# apollo1 register map
Vendor: Ambiq Micro; Series: Apollo; File version: 1.0
CPU: CM4 r1p0, little endian, MPU, FPU, 3 interrupt priority bits
Registers are 32-bit, read-write, reset 0x0 unless marked. A register's access mark holds for its fields unless they carry their own. Offsets are from the block's base; [hi:lo] are bit positions; {n}, {i} and the like mark numbered series; 'fields as' and 'values as' point back to an identical list.

## CTIMER — Counter/Timer
Base 0x40008000
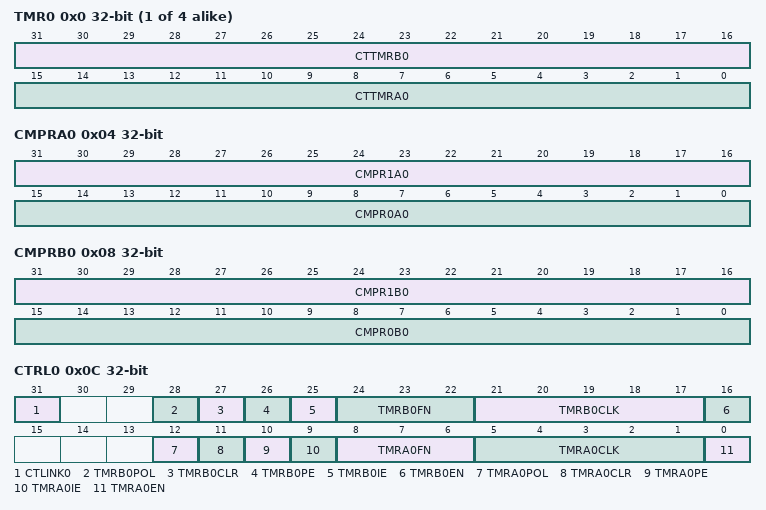
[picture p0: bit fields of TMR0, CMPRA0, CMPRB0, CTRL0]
{0x0+0x10*i} TMR{i} (i=0..3) — Counter/Timer Register
  [31:16] CTTMRB{i} — Counter/Timer B{i}.
  [15:0] CTTMRA{i} — Counter/Timer A{i}.
0x04 CMPRA0 — Counter/Timer A0 Compare Registers
  [31:16] CMPR1A0 — Counter/Timer A0 Compare Register 1. Holds the upper limit for timer half A.
  [15:0] CMPR0A0 — Counter/Timer A0 Compare Register 0. Holds the lower limit for timer half A.
0x08 CMPRB0 — Counter/Timer B0 Compare Registers
  [31:16] CMPR1B0 — Counter/Timer B0 Compare Register 1. Holds the upper limit for timer half B.
  [15:0] CMPR0B0 — Counter/Timer B0 Compare Register 0. Holds the lower limit for timer half B.
0x0C CTRL0 — Counter/Timer Control
  [31] CTLINK0 — Counter/Timer A0/B0 Link bit.
    0=TWO_16BIT_TIMERS (Use A0/B0 timers as two independent 16-bit timers (default). value.); 1=32BIT_TIMER (Link A0/B0 timers into a single 32-bit timer. value.)
  [28] TMRB0POL — Counter/Timer B0 output polarity.
    0=NORMAL (The polarity of the TMRPINB0 pin is the same as the timer output. value.); 1=INVERTED (The polarity of the TMRPINB0 pin is the inverse of the timer output. value.)
  [27] TMRB0CLR — Counter/Timer B0 Clear bit.
    0=RUN (Allow counter/timer B0 to run value.); 1=CLEAR (Holds counter/timer B0 at 0x0000. value.)
  [26] TMRB0PE — Counter/Timer B0 Output Enable bit.
    0=DIS (Counter/Timer B holds the TMRPINB signal at the value TMRB0POL. value.); 1=EN (Enable counter/timer B0 to generate a signal on TMRPINB. value.)
  [25] TMRB0IE — Counter/Timer B0 Interrupt Enable bit.
    0=DIS (Disable counter/timer B0 from generating an interrupt. value.); 1=EN (Enable counter/timer B0 to generate an interrupt. value.)
  [24:22] TMRB0FN — Counter/Timer B0 Function Select.
    0=SINGLECOUNT (Single count (output toggles and sticks). Count to CMPR0B0, stop. value.); 1=REPEATEDCOUNT (Repeated count (periodic 1-clock-cycle-wide pulses). Count to CMPR0B0, restart. value.); 2=PULSE_ONCE (Pulse once (aka one-shot). Count to CMPR0B0, assert, count to CMPR1B, deassert, stop. value.); 3=PULSE_CONT (Pulse continously. Count to CMPR0B0, assert, count to CMPR1B0, deassert, restart. value.); 4=CONTINUOUS (Continuous run (aka Free Run). Count continuously. value.)
  [21:17] TMRB0CLK — Counter/Timer B0 Clock Select.
    0=TMRPIN (Clock source is TMRPINB. value.); 1=HFRC (Clock source is the HFRC value.); 2=HFRC_DIV8 (Clock source is HFRC / 8 value.); 3=HFRC_DIV128 (Clock source is HFRC / 128 value.); 4=HFRC_DIV512 (Clock source is HFRC / 512 value.); 5=HFRC_DIV2K (Clock source is HFRC / 2048 value.); 6=XT (Clock source is the XT (uncalibrated). value.); 7=XT_DIV2 (Clock source is XT / 2 value.); 8=XT_DIV16 (Clock source is XT / 16 value.); 9=XT_DIV256 (Clock source is XT / 256 value.); 10=LFRC_DIV2 (Clock source is LFRC / 2 value.); 11=LFRC_DIV32 (Clock source is LFRC / 32 value.); 12=LFRC_DIV1K (Clock source is LFRC / 1024 value.); 13=LFRC (Clock source is LFRC / 16K value.); 14=RTC_100HZ (Clock source is 100 Hz from the current RTC oscillator. value.); 15=HCLK (Clock source is HCLK. value.); 16=BUCKB (Clock source is buck converter stream B. value.)
  [16] TMRB0EN — Counter/Timer B0 Enable bit.
    0=DIS (Counter/Timer B0 Disable. value.); 1=EN (Counter/Timer B0 Enable. value.)
  [12] TMRA0POL — Counter/Timer A0 output polarity.
    0=NORMAL (The polarity of the TMRPINA0 pin is the same as the timer output. value.); 1=INVERTED (The polarity of the TMRPINA0 pin is the inverse of the timer output. value.)
  [11] TMRA0CLR — Counter/Timer A0 Clear bit.
    0=RUN (Allow counter/timer A0 to run value.); 1=CLEAR (Holds counter/timer A0 at 0x0000. value.)
  [10] TMRA0PE — Counter/Timer A0 Output Enable bit.
    0=DIS (Counter/Timer A holds the TMRPINA signal at the value TMRA0POL. value.); 1=EN (Enable counter/timer B0 to generate a signal on TMRPINB. value.)
  [9] TMRA0IE — Counter/Timer A0 Interrupt Enable bit.
    0=DIS (Disable counter/timer A0 from generating an interrupt. value.); 1=EN (Enable counter/timer A0 to generate an interrupt. value.)
  [8:6] TMRA0FN — Counter/Timer A0 Function Select.
    0=SINGLECOUNT (Single count (output toggles and sticks). Count to CMPR0A0, stop. value.); 1=REPEATEDCOUNT (Repeated count (periodic 1-clock-cycle-wide pulses). Count to CMPR0A0, restart. value.); 2=PULSE_ONCE (Pulse once (aka one-shot). Count to CMPR0A0, assert, count to CMPR1B, deassert, stop. value.); 3=PULSE_CONT (Pulse continously. Count to CMPR0A0, assert, count to CMPR1A0, deassert, restart. value.); 4=CONTINUOUS (Continuous run (aka Free Run). Count continuously. value.)
  [5:1] TMRA0CLK — Counter/Timer A0 Clock Select.
    0=TMRPIN (Clock source is TMRPINA. value.); 1=HFRC (Clock source is the HFRC value.); 2=HFRC_DIV8 (Clock source is HFRC / 8 value.); 3=HFRC_DIV128 (Clock source is HFRC / 128 value.); 4=HFRC_DIV512 (Clock source is HFRC / 512 value.); 5=HFRC_DIV2K (Clock source is HFRC / 2048 value.); 6=XT (Clock source is the XT (uncalibrated). value.); 7=XT_DIV2 (Clock source is XT / 2 value.); 8=XT_DIV16 (Clock source is XT / 16 value.); 9=XT_DIV256 (Clock source is XT / 256 value.); 10=LFRC_DIV2 (Clock source is LFRC / 2 value.); 11=LFRC_DIV32 (Clock source is LFRC / 32 value.); 12=LFRC_DIV1K (Clock source is LFRC / 1024 value.); 13=LFRC (Clock source is LFRC / 16K value.); 14=RTC_100HZ (Clock source is 100 Hz from the current RTC oscillator. value.); 15=HCLK (Clock source is HCLK. value.); 16=BUCKA (Clock source is buck converter stream A. value.)
  [0] TMRA0EN — Counter/Timer A0 Enable bit.
    0=DIS (Counter/Timer A0 Disable. value.); 1=EN (Counter/Timer A0 Enable. value.)
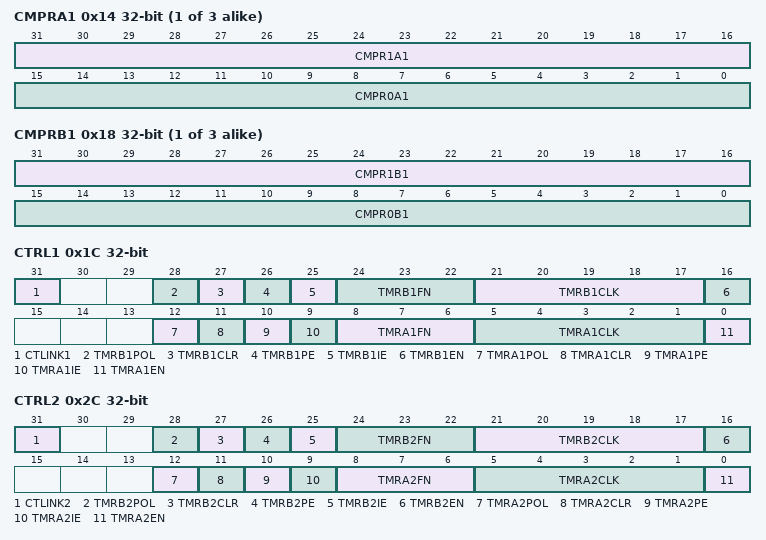
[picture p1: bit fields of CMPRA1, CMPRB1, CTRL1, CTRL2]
{0x4+0x10*i} CMPRA{i} (i=1..3) — Counter/Timer A{i} Compare Registers
  [31:16] CMPR1A{i} — Counter/Timer A{i} Compare Register 1.
  [15:0] CMPR0A{i} — Counter/Timer A{i} Compare Register 0.
{0x8+0x10*i} CMPRB{i} (i=1..3) — Counter/Timer B{i} Compare Registers
  [31:16] CMPR1B{i} — Counter/Timer B{i} Compare Register 1.
  [15:0] CMPR0B{i} — Counter/Timer B{i} Compare Register 0.
0x1C CTRL1 — Counter/Timer Control
  [31] CTLINK1 — Counter/Timer A1/B1 Link bit.
    0=TWO_16BIT_TIMERS (Use A0/B0 timers as two independent 16-bit timers (default). value.); 1=32BIT_TIMER (Link A1/B1 timers into a single 32-bit timer. value.)
  [28] TMRB1POL — Counter/Timer B1 output polarity.
    0=NORMAL (The polarity of the TMRPINB1 pin is the same as the timer output. value.); 1=INVERTED (The polarity of the TMRPINB1 pin is the inverse of the timer output. value.)
  [27] TMRB1CLR — Counter/Timer B1 Clear bit.
    0=RUN (Allow counter/timer B1 to run value.); 1=CLEAR (Holds counter/timer B1 at 0x0000. value.)
  [26] TMRB1PE — Counter/Timer B1 Output Enable bit.
    0=DIS (Counter/Timer B holds the TMRPINB signal at the value TMRB1POL. value.); 1=EN (Enable counter/timer B1 to generate a signal on TMRPINB. value.)
  [25] TMRB1IE — Counter/Timer B1 Interrupt Enable bit.
    0=DIS (Disable counter/timer B1 from generating an interrupt. value.); 1=EN (Enable counter/timer B1 to generate an interrupt. value.)
  [24:22] TMRB1FN — Counter/Timer B1 Function Select.
    0=SINGLECOUNT (Single count (output toggles and sticks). Count to CMPR0B1, stop. value.); 1=REPEATEDCOUNT (Repeated count (periodic 1-clock-cycle-wide pulses). Count to CMPR0B1, restart. value.); 2=PULSE_ONCE (Pulse once (aka one-shot). Count to CMPR0B1, assert, count to CMPR1B, deassert, stop. value.); 3=PULSE_CONT (Pulse continously. Count to CMPR0B1, assert, count to CMPR1B1, deassert, restart. value.); 4=CONTINUOUS (Continuous run (aka Free Run). Count continuously. value.)
  [21:17] TMRB1CLK — Counter/Timer B1 Clock Select.
    values as CTRL0.TMRB0CLK
  [16] TMRB1EN — Counter/Timer B1 Enable bit.
    0=DIS (Counter/Timer B1 Disable. value.); 1=EN (Counter/Timer B1 Enable. value.)
  [12] TMRA1POL — Counter/Timer A1 output polarity.
    0=NORMAL (The polarity of the TMRPINA1 pin is the same as the timer output. value.); 1=INVERTED (The polarity of the TMRPINA1 pin is the inverse of the timer output. value.)
  [11] TMRA1CLR — Counter/Timer A1 Clear bit.
    0=RUN (Allow counter/timer A1 to run value.); 1=CLEAR (Holds counter/timer A1 at 0x0000. value.)
  [10] TMRA1PE — Counter/Timer A1 Output Enable bit.
    0=DIS (Counter/Timer A holds the TMRPINA signal at the value TMRA1POL. value.); 1=EN (Enable counter/timer A1 to generate a signal on TMRPINA. value.)
  [9] TMRA1IE — Counter/Timer A1 Interrupt Enable bit.
    0=DIS (Disable counter/timer A1 from generating an interrupt. value.); 1=EN (Enable counter/timer A1 to generate an interrupt. value.)
  [8:6] TMRA1FN — Counter/Timer A1 Function Select.
    0=SINGLECOUNT (Single count (output toggles and sticks). Count to CMPR0A1, stop. value.); 1=REPEATEDCOUNT (Repeated count (periodic 1-clock-cycle-wide pulses). Count to CMPR0A1, restart. value.); 2=PULSE_ONCE (Pulse once (aka one-shot). Count to CMPR0A1, assert, count to CMPR1B, deassert, stop. value.); 3=PULSE_CONT (Pulse continously. Count to CMPR0A1, assert, count to CMPR1A1, deassert, restart. value.); 4=CONTINUOUS (Continuous run (aka Free Run). Count continuously. value.)
  [5:1] TMRA1CLK — Counter/Timer A1 Clock Select.
    0=TMRPIN (Clock source is TMRPINA. value.); 1=HFRC (Clock source is the HFRC value.); 2=HFRC_DIV8 (Clock source is the HFRC / 8 value.); 3=HFRC_DIV128 (Clock source is HFRC / 128 value.); 4=HFRC_DIV512 (Clock source is HFRC / 512 value.); 5=HFRC_DIV2K (Clock source is HFRC / 2048 value.); 6=XT (Clock source is the XT (uncalibrated). value.); 7=XT_DIV2 (Clock source is XT / 2 value.); 8=XT_DIV16 (Clock source is XT / 16 value.); 9=XT_DIV256 (Clock source is XT / 256 value.); 10=LFRC_DIV2 (Clock source is LFRC / 2 value.); 11=LFRC_DIV32 (Clock source is LFRC / 32 value.); 12=LFRC_DIV1K (Clock source is LFRC / 1024 value.); 13=LFRC (Clock source is LFRC / 16K value.); 14=RTC_100HZ (Clock source is 100 Hz from the current RTC oscillator. value.); 15=HCLK (Clock source is HCLK. value.); 16=BUCKA (Clock source is buck converter stream A. value.)
  [0] TMRA1EN — Counter/Timer A1 Enable bit.
    0=DIS (Counter/Timer A1 Disable. value.); 1=EN (Counter/Timer A1 Enable. value.)
0x2C CTRL2 — Counter/Timer Control
  [31] CTLINK2 — Counter/Timer A2/B2 Link bit.
    0=TWO_16BIT_TIMERS (Use A0/B0 timers as two independent 16-bit timers (default). value.); 1=32BIT_TIMER (Link A2/B2 timers into a single 32-bit timer. value.)
  [28] TMRB2POL — Counter/Timer B2 output polarity.
    0=NORMAL (The polarity of the TMRPINB2 pin is the same as the timer output. value.); 1=INVERTED (The polarity of the TMRPINB2 pin is the inverse of the timer output. value.)
  [27] TMRB2CLR — Counter/Timer B2 Clear bit.
    0=RUN (Allow counter/timer B2 to run value.); 1=CLEAR (Holds counter/timer B2 at 0x0000. value.)
  [26] TMRB2PE — Counter/Timer B2 Output Enable bit.
    0=DIS (Counter/Timer B holds the TMRPINB signal at the value TMRB2POL. value.); 1=EN (Enable counter/timer B2 to generate a signal on TMRPINB. value.)
  [25] TMRB2IE — Counter/Timer B2 Interrupt Enable bit.
    0=DIS (Disable counter/timer B2 from generating an interrupt. value.); 1=EN (Enable counter/timer B2 to generate an interrupt. value.)
  [24:22] TMRB2FN — Counter/Timer B2 Function Select.
    0=SINGLECOUNT (Single count (output toggles and sticks). Count to CMPR0B2, stop. value.); 1=REPEATEDCOUNT (Repeated count (periodic 1-clock-cycle-wide pulses). Count to CMPR0B2, restart. value.); 2=PULSE_ONCE (Pulse once (aka one-shot). Count to CMPR0B2, assert, count to CMPR1B, deassert, stop. value.); 3=PULSE_CONT (Pulse continously. Count to CMPR0B2, assert, count to CMPR1B2, deassert, restart. value.); 4=CONTINUOUS (Continuous run (aka Free Run). Count continuously. value.)
  [21:17] TMRB2CLK — Counter/Timer B2 Clock Select.
    0=TMRPIN (Clock source is TMRPINB. value.); 1=HFRC (Clock source is the HFRC value.); 2=HFRC_DIV8 (Clock source is HFRC / 8 value.); 3=HFRC_DIV128 (Clock source is HFRC / 128 value.); 4=HFRC_DIV512 (Clock source is HFRC / 512 value.); 5=HFRC_DIV2K (Clock source is HFRC / 2048 value.); 6=XT (Clock source is the XT (uncalibrated). value.); 7=XT_DIV2 (Clock source is XT / 2 value.); 8=XT_DIV16 (Clock source is XT / 16 value.); 9=XT_DIV256 (Clock source is XT / 256 value.); 10=LFRC_DIV2 (Clock source is LFRC / 2 value.); 11=LFRC_DIV32 (Clock source is LFRC / 32 value.); 12=LFRC_DIV1K (Clock source is LFRC / 1024 value.); 13=LFRC (Clock source is LFRC / 16K value.); 14=RTC_100HZ (Clock source is 100 Hz from the current RTC oscillator. value.); 15=HCLK (Clock source is HCLK. value.); 16=BUCKA (Clock source is buck converter stream A. value.)
  [16] TMRB2EN — Counter/Timer B2 Enable bit.
    0=DIS (Counter/Timer B2 Disable. value.); 1=EN (Counter/Timer B2 Enable. value.)
  [12] TMRA2POL — Counter/Timer A2 output polarity.
    0=NORMAL (The polarity of the TMRPINA2 pin is the same as the timer output. value.); 1=INVERTED (The polarity of the TMRPINA2 pin is the inverse of the timer output. value.)
  [11] TMRA2CLR — Counter/Timer A2 Clear bit.
    0=RUN (Allow counter/timer A2 to run value.); 1=CLEAR (Holds counter/timer A2 at 0x0000. value.)
  [10] TMRA2PE — Counter/Timer A2 Output Enable bit.
    0=DIS (Counter/Timer A holds the TMRPINA signal at the value TMRA2POL. value.); 1=EN (Enable counter/timer A2 to generate a signal on TMRPINA. value.)
  [9] TMRA2IE — Counter/Timer A2 Interrupt Enable bit.
    0=DIS (Disable counter/timer A2 from generating an interrupt. value.); 1=EN (Enable counter/timer A2 to generate an interrupt. value.)
  [8:6] TMRA2FN — Counter/Timer A2 Function Select.
    0=SINGLECOUNT (Single count (output toggles and sticks). Count to CMPR0A2, stop. value.); 1=REPEATEDCOUNT (Repeated count (periodic 1-clock-cycle-wide pulses). Count to CMPR0A2, restart. value.); 2=PULSE_ONCE (Pulse once (aka one-shot). Count to CMPR0A2, assert, count to CMPR1B, deassert, stop. value.); 3=PULSE_CONT (Pulse continously. Count to CMPR0A2, assert, count to CMPR1A2, deassert, restart. value.); 4=CONTINUOUS (Continuous run (aka Free Run). Count continuously. value.)
  [5:1] TMRA2CLK — Counter/Timer A2 Clock Select.
    0=TMRPIN (Clock source is TMRPINA. value.); 1=HFRC (Clock source is the HFRC value.); 2=HFRC_DIV8 (Clock source is HFRC / 8 value.); 3=HFRC_DIV128 (Clock source is HFRC / 128 value.); 4=HFRC_DIV512 (Clock source is HFRC / 512 value.); 5=HFRC_DIV2K (Clock source is HFRC / 2048 value.); 6=XT (Clock source is the XT (uncalibrated). value.); 7=XT_DIV2 (Clock source is XT / 2 value.); 8=XT_DIV16 (Clock source is XT / 16 value.); 9=XT_DIV256 (Clock source is XT / 256 value.); 10=LFRC_DIV2 (Clock source is LFRC / 2 value.); 11=LFRC_DIV32 (Clock source is LFRC / 32 value.); 12=LFRC_DIV1K (Clock source is LFRC / 1024 value.); 13=LFRC (Clock source is LFRC / 16K value.); 14=RTC_100HZ (Clock source is 100 Hz from the current RTC oscillator. value.); 15=HCLK (Clock source is HCLK. value.); 16=BUCKB (Clock source is buck converter stream B. value.)
  [0] TMRA2EN — Counter/Timer A2 Enable bit.
    0=DIS (Counter/Timer A2 Disable. value.); 1=EN (Counter/Timer A2 Enable. value.)
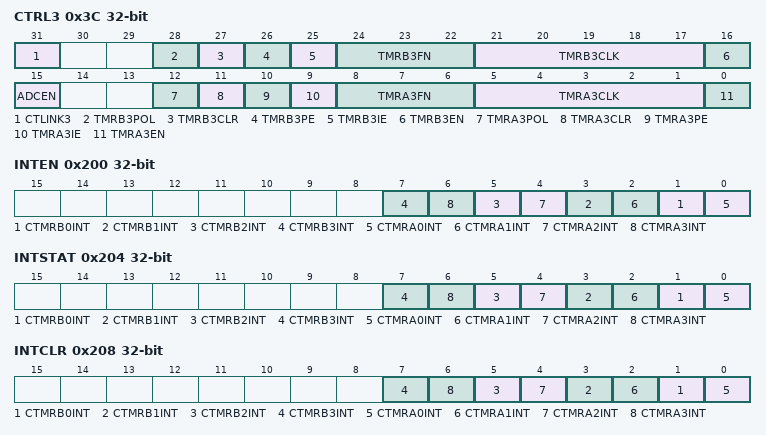
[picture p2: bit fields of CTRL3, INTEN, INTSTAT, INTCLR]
0x3C CTRL3 — Counter/Timer Control
  [31] CTLINK3 — Counter/Timer A/B Link bit.
    0=TWO_16BIT_TIMERS (Use A0/B0 timers as two independent 16-bit timers (default). value.); 1=32BIT_TIMER (Link A3/B3 timers into a single 32-bit timer. value.)
  [28] TMRB3POL — Counter/Timer B3 output polarity.
    0=NORMAL (The polarity of the TMRPINB3 pin is the same as the timer output. value.); 1=INVERTED (The polarity of the TMRPINB3 pin is the inverse of the timer output. value.)
  [27] TMRB3CLR — Counter/Timer B3 Clear bit.
    0=RUN (Allow counter/timer B3 to run. value.); 1=CLEAR (Holds counter/timer B3 at 0x0000. value.)
  [26] TMRB3PE — Counter/Timer B3 Output Enable bit.
    0=DIS (Counter/Timer B holds the TMRPINB signal at the value TMRB3POL. value.); 1=EN (Enable counter/timer B3 to generate a signal on TMRPINB. value.)
  [25] TMRB3IE — Counter/Timer B3 Interrupt Enable bit.
    0=DIS (Disable counter/timer B3 from generating an interrupt. value.); 1=EN (Enable counter/timer B3 to generate an interrupt. value.)
  [24:22] TMRB3FN — Counter/Timer B3 Function Select.
    0=SINGLECOUNT (Single count (output toggles and sticks). Count to CMPR0B3, stop. value.); 1=REPEATEDCOUNT (Repeated count (periodic 1-clock-cycle-wide pulses). Count to CMPR0B3, restart. value.); 2=PULSE_ONCE (Pulse once (aka one-shot). Count to CMPR0B3, assert, count to CMPR1B, deassert, stop. value.); 3=PULSE_CONT (Pulse continously. Count to CMPR0B3, assert, count to CMPR1B3, deassert, restart. value.); 4=CONTINUOUS (Continuous run (aka Free Run). Count continuously. value.)
  [21:17] TMRB3CLK — Counter/Timer B3 Clock Select.
    values as CTRL2.TMRB2CLK
  [16] TMRB3EN — Counter/Timer B3 Enable bit.
    0=DIS (Counter/Timer B3 Disable. value.); 1=EN (Counter/Timer B3 Enable. value.)
  [15] ADCEN — Special Timer A3 enable for ADC function.
  [12] TMRA3POL — Counter/Timer A3 output polarity.
    0=NORMAL (The polarity of the TMRPINA3 pin is the same as the timer output. value.); 1=INVERTED (The polarity of the TMRPINA3 pin is the inverse of the timer output. value.)
  [11] TMRA3CLR — Counter/Timer A3 Clear bit.
    1=CLEAR (Holds counter/timer A3 at 0x0000. value.)
  [10] TMRA3PE — Counter/Timer A3 Output Enable bit.
    0=DIS (Counter/Timer A holds the TMRPINA signal at the value TMRA3POL. value.); 1=EN (Enable counter/timer A3 to generate a signal on TMRPINA. value.)
  [9] TMRA3IE — Counter/Timer A3 Interrupt Enable bit.
    0=DIS (Disable counter/timer A3 from generating an interrupt. value.); 1=EN (Enable counter/timer A3 to generate an interrupt. value.)
  [8:6] TMRA3FN — Counter/Timer A3 Function Select.
    0=SINGLECOUNT (Single count (output toggles and sticks). Count to CMPR0A3, stop. value.); 1=REPEATEDCOUNT (Repeated count (periodic 1-clock-cycle-wide pulses). Count to CMPR0A3, restart. value.); 2=PULSE_ONCE (Pulse once (aka one-shot). Count to CMPR0A3, assert, count to CMPR1B, deassert, stop. value.); 3=PULSE_CONT (Pulse continously. Count to CMPR0A3, assert, count to CMPR1A3, deassert, restart. value.); 4=CONTINUOUS (Continuous run (aka Free Run). Count continuously. value.)
  [5:1] TMRA3CLK — Counter/Timer A3 Clock Select.
    values as CTRL2.TMRA2CLK
  [0] TMRA3EN — Counter/Timer A3 Enable bit.
    0=DIS (Counter/Timer A3 Disable. value.); 1=EN (Counter/Timer A3 Enable. value.)
0x200 INTEN — Counter/Timer Interrupts: Enable
  [2n+1] CTMRB{n}INT (n=0..3) — Counter/Timer B{n} interrupt.
  [2n] CTMRA{n}INT (n=0..3) — Counter/Timer A{n} interrupt.
0x204 INTSTAT — Counter/Timer Interrupts: Status
  fields as INTEN
0x208 INTCLR — Counter/Timer Interrupts: Clear
  fields as INTEN
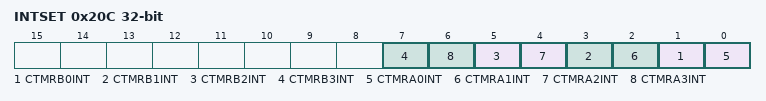
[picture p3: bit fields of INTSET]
0x20C INTSET — Counter/Timer Interrupts: Set
  fields as INTEN
